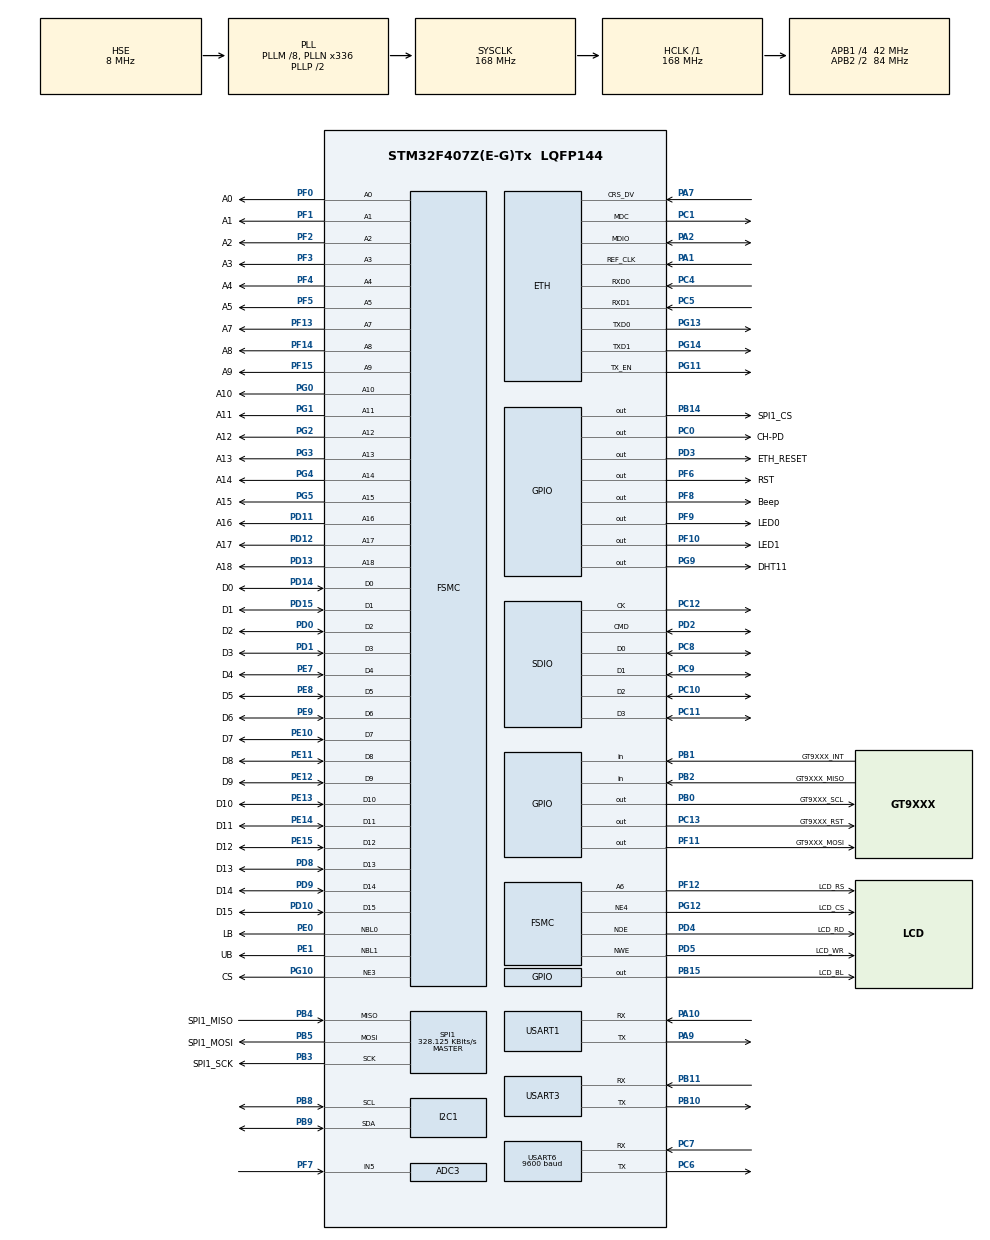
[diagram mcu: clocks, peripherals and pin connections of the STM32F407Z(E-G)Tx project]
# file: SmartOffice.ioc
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ADC3.Channel-0\#ChannelRegularConversion=ADC_CHANNEL_5
ADC3.NbrOfConversionFlag=1
ADC3.Rank-0\#ChannelRegularConversion=1
ADC3.SamplingTime-0\#ChannelRegularConversion=ADC_SAMPLETIME_3CYCLES
Dma.Request0=SDIO_RX
Dma.Request1=SDIO_TX
Dma.Request2=USART3_RX
Dma.Request3=USART3_TX
Dma.SDIO_RX.0.Direction=DMA_PERIPH_TO_MEMORY
Dma.SDIO_RX.0.FIFOMode=DMA_FIFOMODE_ENABLE
Dma.SDIO_RX.0.FIFOThreshold=DMA_FIFO_THRESHOLD_FULL
Dma.SDIO_RX.0.Instance=DMA2_Stream3
Dma.SDIO_RX.0.MemBurst=DMA_MBURST_SINGLE
Dma.SDIO_RX.0.MemDataAlignment=DMA_MDATAALIGN_BYTE
Dma.SDIO_RX.0.MemInc=DMA_MINC_ENABLE
Dma.SDIO_RX.0.Mode=DMA_PFCTRL
Dma.SDIO_RX.0.PeriphBurst=DMA_PBURST_INC4
Dma.SDIO_RX.0.PeriphDataAlignment=DMA_PDATAALIGN_WORD
Dma.SDIO_RX.0.PeriphInc=DMA_PINC_DISABLE
Dma.SDIO_RX.0.Priority=DMA_PRIORITY_LOW
Dma.SDIO_TX.1.Direction=DMA_MEMORY_TO_PERIPH
Dma.SDIO_TX.1.FIFOMode=DMA_FIFOMODE_ENABLE
Dma.SDIO_TX.1.FIFOThreshold=DMA_FIFO_THRESHOLD_FULL
Dma.SDIO_TX.1.Instance=DMA2_Stream6
Dma.SDIO_TX.1.MemBurst=DMA_MBURST_SINGLE
Dma.SDIO_TX.1.MemDataAlignment=DMA_MDATAALIGN_BYTE
Dma.SDIO_TX.1.MemInc=DMA_MINC_ENABLE
Dma.SDIO_TX.1.Mode=DMA_PFCTRL
Dma.SDIO_TX.1.PeriphBurst=DMA_PBURST_INC4
Dma.SDIO_TX.1.PeriphDataAlignment=DMA_PDATAALIGN_WORD
Dma.SDIO_TX.1.PeriphInc=DMA_PINC_DISABLE
Dma.SDIO_TX.1.Priority=DMA_PRIORITY_LOW
Dma.USART3_RX.2.Direction=DMA_PERIPH_TO_MEMORY
Dma.USART3_RX.2.FIFOMode=DMA_FIFOMODE_DISABLE
Dma.USART3_RX.2.Instance=DMA1_Stream1
Dma.USART3_RX.2.MemDataAlignment=DMA_MDATAALIGN_BYTE
Dma.USART3_RX.2.MemInc=DMA_MINC_ENABLE
Dma.USART3_RX.2.Mode=DMA_CIRCULAR
Dma.USART3_RX.2.PeriphDataAlignment=DMA_PDATAALIGN_BYTE
Dma.USART3_RX.2.PeriphInc=DMA_PINC_DISABLE
Dma.USART3_RX.2.Priority=DMA_PRIORITY_LOW
Dma.USART3_TX.3.Direction=DMA_MEMORY_TO_PERIPH
Dma.USART3_TX.3.FIFOMode=DMA_FIFOMODE_DISABLE
Dma.USART3_TX.3.Instance=DMA1_Stream3
Dma.USART3_TX.3.MemDataAlignment=DMA_MDATAALIGN_BYTE
Dma.USART3_TX.3.MemInc=DMA_MINC_ENABLE
Dma.USART3_TX.3.Mode=DMA_NORMAL
Dma.USART3_TX.3.PeriphDataAlignment=DMA_PDATAALIGN_BYTE
Dma.USART3_TX.3.PeriphInc=DMA_PINC_DISABLE
Dma.USART3_TX.3.Priority=DMA_PRIORITY_LOW
ETH.MediaInterface=ETH_MEDIA_INTERFACE_RMII
ETH.PHY_DUPLEX_STATUS=0x2000
ETH.PHY_Name_RMII=userPHY
ETH.PHY_SPEED_STATUS=0x4010
ETH.PHY_SR=0x11
ETH.PhyAddress=0
FATFS._CODE_PAGE=936
FATFS._FS_EXFAT=1
FATFS._USE_LABEL=1
FATFS._USE_LFN=3
FREERTOS.HEAP_NUMBER=5
FREERTOS.MEMORY_ALLOCATION=0
FREERTOS.Tasks01=WebServer,2,256,WebServer_Task,Default,NULL,Dynamic,NULL,NULL;Touch,1,128,Touch_Task,Default,NULL,Dynamic,NULL,NULL;IOT,0,128,IOT_Task,Default,NULL,Dynamic,NULL,NULL;GUI,-1,512,GUI_Task,Default,NULL,Dynamic,NULL,NULL
FREERTOS.configTOTAL_HEAP_SIZE=15360
FSMC.AddressSetupTime1=2
FSMC.BusTurnAroundDuration1=0
FSMC.DataSetupTime1=8
FSMC.DataSetupTime2=60
FSMC.ExtendedAddressSetupTime2=9
FSMC.ExtendedDataSetupTime2=9
FSMC.ExtendedMode2=FSMC_EXTENDED_MODE_ENABLE
FSMC.WriteOperation1=FSMC_WRITE_OPERATION_ENABLE
LWIP.GATEWAY_ADDRESS=010.010.001.001
LWIP.IP_ADDRESS=010.010.001.022
LWIP.LWIP_DHCP=1
LWIP.LWIP_HTTPD=0
LWIP.LWIP_NETIF_LINK_CALLBACK=1
LWIP.MEMP_MEM_MALLOC=1
LWIP.MEM_SIZE=16384
LWIP.NETMASK_ADDRESS=255.255.255.000
LWIP.Version=v2.0.3_Cube
Mcu.Family=STM32F4
Mcu.Name=STM32F407Z(E-G)Tx
Mcu.Package=LQFP144
NVIC.DMA1_Stream1_IRQn=true\:7\:0\:true\:false\:true\:true\:false\:true
NVIC.DMA1_Stream3_IRQn=true\:7\:0\:true\:false\:true\:true\:false\:true
NVIC.DMA2_Stream3_IRQn=true\:6\:0\:true\:false\:true\:true\:false\:true
NVIC.DMA2_Stream6_IRQn=true\:6\:0\:true\:false\:true\:true\:false\:true
NVIC.ETH_IRQn=true\:5\:0\:false\:false\:true\:true\:true\:true
NVIC.PriorityGroup=NVIC_PRIORITYGROUP_4
NVIC.SDIO_IRQn=true\:5\:0\:false\:false\:true\:true\:true\:true
NVIC.TIM1_UP_TIM10_IRQn=true\:0\:0\:false\:false\:true\:false\:false\:true
NVIC.TimeBase=TIM1_UP_TIM10_IRQn
NVIC.TimeBaseIP=TIM1
NVIC.USART3_IRQn=true\:6\:0\:true\:false\:true\:true\:true\:true
PA1.Mode=RMII
PA1.Signal=ETH_REF_CLK
PA10.Mode=Asynchronous
PA10.Signal=USART1_RX
PA13.Mode=Serial_Wire
PA13.Signal=SYS_JTMS-SWDIO
PA14.Mode=Serial_Wire
PA14.Signal=SYS_JTCK-SWCLK
PA2.Mode=RMII
PA2.Signal=ETH_MDIO
PA7.Mode=RMII
PA7.Signal=ETH_CRS_DV
PA9.Mode=Asynchronous
PA9.Signal=USART1_TX
PB0.GPIO_Label=GT9XXX_SCL
PB0.GPIO_PuPd=GPIO_PULLUP
PB0.GPIO_Speed=GPIO_SPEED_FREQ_VERY_HIGH
PB0.Signal=GPIO_Output
PB1.GPIO_Label=GT9XXX_INT
PB1.Signal=GPIO_Input
PB10.Mode=Asynchronous
PB10.Signal=USART3_TX
PB11.Mode=Asynchronous
PB11.Signal=USART3_RX
PB14.GPIO_Label=SPI1_CS
PB14.GPIO_PuPd=GPIO_PULLUP
PB14.GPIO_Speed=GPIO_SPEED_FREQ_HIGH
PB14.PinState=GPIO_PIN_SET
PB14.Signal=GPIO_Output
PB15.GPIO_Label=LCD_BL
PB15.GPIO_PuPd=GPIO_PULLDOWN
PB15.GPIO_Speed=GPIO_SPEED_FREQ_HIGH
PB15.PinState=GPIO_PIN_SET
PB15.Signal=GPIO_Output
PB2.GPIO_Label=GT9XXX_MISO
PB2.GPIO_PuPd=GPIO_PULLUP
PB2.Signal=GPIO_Input
PB3.GPIO_Label=SPI1_SCK
PB3.GPIO_PuPd=GPIO_PULLUP
PB3.Mode=Full_Duplex_Master
PB3.Signal=SPI1_SCK
PB4.GPIO_Label=SPI1_MISO
PB4.GPIO_PuPd=GPIO_PULLUP
PB4.Mode=Full_Duplex_Master
PB4.Signal=SPI1_MISO
PB5.GPIO_Label=SPI1_MOSI
PB5.GPIO_PuPd=GPIO_PULLUP
PB5.Mode=Full_Duplex_Master
PB5.Signal=SPI1_MOSI
PB8.Mode=I2C
PB8.Signal=I2C1_SCL
PB9.Mode=I2C
PB9.Signal=I2C1_SDA
PC0.GPIO_Label=CH-PD
PC0.GPIO_PuPd=GPIO_NOPULL
PC0.GPIO_Speed=GPIO_SPEED_FREQ_LOW
PC0.PinState=GPIO_PIN_SET
PC0.Signal=GPIO_Output
PC1.Mode=RMII
PC1.Signal=ETH_MDC
PC10.GPIO_PuPd=GPIO_PULLUP
PC10.Mode=SD_4_bits_Wide_bus
PC10.Signal=SDIO_D2
PC11.GPIO_PuPd=GPIO_PULLUP
PC11.Mode=SD_4_bits_Wide_bus
PC11.Signal=SDIO_D3
PC12.GPIO_PuPd=GPIO_PULLUP
PC12.Mode=SD_4_bits_Wide_bus
PC12.Signal=SDIO_CK
PC13-ANTI_TAMP.GPIO_Label=GT9XXX_RST
PC13-ANTI_TAMP.GPIO_PuPd=GPIO_PULLUP
PC13-ANTI_TAMP.Signal=GPIO_Output
PC4.Mode=RMII
PC4.Signal=ETH_RXD0
PC5.Mode=RMII
PC5.Signal=ETH_RXD1
PC6.Mode=Asynchronous
PC6.Signal=USART6_TX
PC7.Mode=Asynchronous
PC7.Signal=USART6_RX
PC8.GPIO_PuPd=GPIO_PULLUP
PC8.Mode=SD_4_bits_Wide_bus
PC8.Signal=SDIO_D0
PC9.GPIO_PuPd=GPIO_PULLUP
PC9.Mode=SD_4_bits_Wide_bus
PC9.Signal=SDIO_D1
PD0.GPIO_Label=D2
PD0.GPIO_PuPd=GPIO_PULLUP
PD0.Signal=FSMC_D2_DA2
PD1.GPIO_Label=D3
PD1.GPIO_PuPd=GPIO_PULLUP
PD1.Signal=FSMC_D3_DA3
PD10.GPIO_Label=D15
PD10.GPIO_PuPd=GPIO_PULLUP
PD10.Signal=FSMC_D15_DA15
PD11.GPIO_Label=A16
PD11.GPIO_PuPd=GPIO_PULLUP
PD11.Signal=FSMC_A16_CLE
PD12.GPIO_Label=A17
PD12.GPIO_PuPd=GPIO_PULLUP
PD12.Signal=FSMC_A17_ALE
PD13.GPIO_Label=A18
PD13.GPIO_PuPd=GPIO_PULLUP
PD13.Signal=FSMC_A18
PD14.GPIO_Label=D0
PD14.GPIO_PuPd=GPIO_PULLUP
PD14.Signal=FSMC_D0_DA0
PD15.GPIO_Label=D1
PD15.GPIO_PuPd=GPIO_PULLUP
PD15.Signal=FSMC_D1_DA1
PD2.GPIO_PuPd=GPIO_PULLUP
PD2.Mode=SD_4_bits_Wide_bus
PD2.Signal=SDIO_CMD
PD3.GPIO_Label=ETH_RESET
PD3.GPIO_Speed=GPIO_SPEED_FREQ_VERY_HIGH
PD3.PinState=GPIO_PIN_SET
PD3.Signal=GPIO_Output
PD4.GPIO_Label=LCD_RD
PD4.GPIO_PuPd=GPIO_PULLUP
PD4.Signal=FSMC_NOE
PD5.GPIO_Label=LCD_WR
PD5.GPIO_PuPd=GPIO_PULLUP
PD5.Signal=FSMC_NWE
PD8.GPIO_Label=D13
PD8.GPIO_PuPd=GPIO_PULLUP
PD8.Signal=FSMC_D13_DA13
PD9.GPIO_Label=D14
PD9.GPIO_PuPd=GPIO_PULLUP
PD9.Signal=FSMC_D14_DA14
PE0.GPIO_Label=LB
PE0.GPIO_PuPd=GPIO_PULLUP
PE0.Signal=FSMC_NBL0
PE1.GPIO_Label=UB
PE1.GPIO_PuPd=GPIO_PULLUP
PE1.Signal=FSMC_NBL1
PE10.GPIO_Label=D7
PE10.GPIO_PuPd=GPIO_PULLUP
PE10.Signal=FSMC_D7_DA7
PE11.GPIO_Label=D8
PE11.GPIO_PuPd=GPIO_PULLUP
PE11.Signal=FSMC_D8_DA8
PE12.GPIO_Label=D9
PE12.GPIO_PuPd=GPIO_PULLUP
PE12.Signal=FSMC_D9_DA9
PE13.GPIO_Label=D10
PE13.GPIO_PuPd=GPIO_PULLUP
PE13.Signal=FSMC_D10_DA10
PE14.GPIO_Label=D11
PE14.GPIO_PuPd=GPIO_PULLUP
PE14.Signal=FSMC_D11_DA11
PE15.GPIO_Label=D12
PE15.GPIO_PuPd=GPIO_PULLUP
PE15.Signal=FSMC_D12_DA12
PE7.GPIO_Label=D4
PE7.GPIO_PuPd=GPIO_PULLUP
PE7.Signal=FSMC_D4_DA4
PE8.GPIO_Label=D5
PE8.GPIO_PuPd=GPIO_PULLUP
PE8.Signal=FSMC_D5_DA5
PE9.GPIO_Label=D6
PE9.GPIO_PuPd=GPIO_PULLUP
PE9.Signal=FSMC_D6_DA6
PF0.GPIO_Label=A0
PF0.GPIO_PuPd=GPIO_PULLUP
PF0.Signal=FSMC_A0
PF1.GPIO_Label=A1
PF1.GPIO_PuPd=GPIO_PULLUP
PF1.Signal=FSMC_A1
PF10.GPIO_Label=LED1
PF10.GPIO_ModeDefaultOutputPP=GPIO_MODE_OUTPUT_PP
PF10.GPIO_PuPd=GPIO_PULLUP
PF10.GPIO_Speed=GPIO_SPEED_FREQ_HIGH
PF10.PinState=GPIO_PIN_SET
PF10.Signal=GPIO_Output
PF11.GPIO_Label=GT9XXX_MOSI
PF11.GPIO_ModeDefaultOutputPP=GPIO_MODE_OUTPUT_OD
PF11.GPIO_PuPd=GPIO_PULLUP
PF11.GPIO_Speed=GPIO_SPEED_FREQ_VERY_HIGH
PF11.Signal=GPIO_Output
PF12.GPIO_Label=LCD_RS
PF12.GPIO_PuPd=GPIO_PULLUP
PF12.Signal=FSMC_A6
PF13.GPIO_Label=A7
PF13.GPIO_PuPd=GPIO_PULLUP
PF13.Signal=FSMC_A7
PF14.GPIO_Label=A8
PF14.GPIO_PuPd=GPIO_PULLUP
PF14.Signal=FSMC_A8
PF15.GPIO_Label=A9
PF15.GPIO_PuPd=GPIO_PULLUP
PF15.Signal=FSMC_A9
PF2.GPIO_Label=A2
PF2.GPIO_PuPd=GPIO_PULLUP
PF2.Signal=FSMC_A2
PF3.GPIO_Label=A3
PF3.GPIO_PuPd=GPIO_PULLUP
PF3.Signal=FSMC_A3
PF4.GPIO_Label=A4
PF4.GPIO_PuPd=GPIO_PULLUP
PF4.Signal=FSMC_A4
PF5.GPIO_Label=A5
PF5.GPIO_PuPd=GPIO_PULLUP
PF5.Signal=FSMC_A5
PF6.GPIO_Label=RST
PF6.PinState=GPIO_PIN_SET
PF6.Signal=GPIO_Output
PF7.Mode=IN5
PF7.Signal=ADC3_IN5
PF8.GPIO_Label=Beep
PF8.GPIO_ModeDefaultOutputPP=GPIO_MODE_OUTPUT_PP
PF8.GPIO_PuPd=GPIO_PULLDOWN
PF8.GPIO_Speed=GPIO_SPEED_FREQ_VERY_HIGH
PF8.Signal=GPIO_Output
PF9.GPIO_Label=LED0
PF9.GPIO_PuPd=GPIO_PULLUP
PF9.GPIO_Speed=GPIO_SPEED_FREQ_HIGH
PF9.PinState=GPIO_PIN_SET
PF9.Signal=GPIO_Output
PG0.GPIO_Label=A10
PG0.GPIO_PuPd=GPIO_PULLUP
PG0.Signal=FSMC_A10
PG1.GPIO_Label=A11
PG1.GPIO_PuPd=GPIO_PULLUP
PG1.Signal=FSMC_A11
PG10.GPIO_Label=CS
PG10.GPIO_PuPd=GPIO_PULLUP
PG10.Mode=NorPsramChipSelect3_1
PG10.Signal=FSMC_NE3
PG11.Mode=RMII
PG11.Signal=ETH_TX_EN
PG12.GPIO_Label=LCD_CS
PG12.GPIO_PuPd=GPIO_PULLUP
PG12.Mode=NorPsramChipSelect4_2
PG12.Signal=FSMC_NE4
PG13.Mode=RMII
PG13.Signal=ETH_TXD0
PG14.Mode=RMII
PG14.Signal=ETH_TXD1
PG2.GPIO_Label=A12
PG2.GPIO_PuPd=GPIO_PULLUP
PG2.Signal=FSMC_A12
PG3.GPIO_Label=A13
PG3.GPIO_PuPd=GPIO_PULLUP
PG3.Signal=FSMC_A13
PG4.GPIO_Label=A14
PG4.GPIO_PuPd=GPIO_PULLUP
PG4.Signal=FSMC_A14
PG5.GPIO_Label=A15
PG5.GPIO_PuPd=GPIO_PULLUP
PG5.Signal=FSMC_A15
PG9.GPIO_Label=DHT11
PG9.GPIO_ModeDefaultOutputPP=GPIO_MODE_OUTPUT_OD
PG9.GPIO_PuPd=GPIO_PULLUP
PG9.GPIO_Speed=GPIO_SPEED_FREQ_VERY_HIGH
PG9.PinState=GPIO_PIN_SET
PG9.Signal=GPIO_Output
PH0-OSC_IN.Mode=HSE-External-Oscillator
PH0-OSC_IN.Signal=RCC_OSC_IN
PH1-OSC_OUT.Mode=HSE-External-Oscillator
PH1-OSC_OUT.Signal=RCC_OSC_OUT
ProjectManager.HeapSize=0x400
ProjectManager.StackSize=0x2000
ProjectManager.TargetToolchain=MDK-ARM V5
RCC.48MHZClocksFreq_Value=48000000
RCC.AHBFreq_Value=168000000
RCC.APB1CLKDivider=RCC_HCLK_DIV4
RCC.APB1Freq_Value=42000000
RCC.APB1TimFreq_Value=84000000
RCC.APB2CLKDivider=RCC_HCLK_DIV2
RCC.APB2Freq_Value=84000000
RCC.APB2TimFreq_Value=168000000
RCC.CortexFreq_Value=168000000
RCC.HCLKFreq_Value=168000000
RCC.HSE_VALUE=8000000
RCC.HSI_VALUE=16000000
RCC.LSE_VALUE=32768
RCC.PLLM=8
RCC.PLLN=336
RCC.PLLQ=7
RCC.PLLSourceVirtual=RCC_PLLSOURCE_HSE
RCC.SYSCLKFreq_VALUE=168000000
RCC.SYSCLKSource=RCC_SYSCLKSOURCE_PLLCLK
RCC.VCOOutputFreq_Value=336000000
SDIO.HardwareFlowControl=SDIO_HARDWARE_FLOW_CONTROL_ENABLE
SH.FSMC_A0.0=FSMC_A0,19b-a1
SH.FSMC_A1.0=FSMC_A1,19b-a1
SH.FSMC_A10.0=FSMC_A10,19b-a1
SH.FSMC_A11.0=FSMC_A11,19b-a1
SH.FSMC_A12.0=FSMC_A12,19b-a1
SH.FSMC_A13.0=FSMC_A13,19b-a1
SH.FSMC_A14.0=FSMC_A14,19b-a1
SH.FSMC_A15.0=FSMC_A15,19b-a1
SH.FSMC_A16_CLE.0=FSMC_A16,19b-a1
SH.FSMC_A17_ALE.0=FSMC_A17,19b-a1
SH.FSMC_A18.0=FSMC_A18,19b-a1
SH.FSMC_A2.0=FSMC_A2,19b-a1
SH.FSMC_A3.0=FSMC_A3,19b-a1
SH.FSMC_A4.0=FSMC_A4,19b-a1
SH.FSMC_A5.0=FSMC_A5,19b-a1
SH.FSMC_A6.0=FSMC_A6,A6_2
SH.FSMC_A6.1=FSMC_A6,19b-a1
SH.FSMC_A7.0=FSMC_A7,19b-a1
SH.FSMC_A8.0=FSMC_A8,19b-a1
SH.FSMC_A9.0=FSMC_A9,19b-a1
SH.FSMC_D0_DA0.0=FSMC_D0,16b-d2
SH.FSMC_D0_DA0.1=FSMC_D0,16b-d1
SH.FSMC_D10_DA10.0=FSMC_D10,16b-d2
SH.FSMC_D10_DA10.1=FSMC_D10,16b-d1
SH.FSMC_D11_DA11.0=FSMC_D11,16b-d2
SH.FSMC_D11_DA11.1=FSMC_D11,16b-d1
SH.FSMC_D12_DA12.0=FSMC_D12,16b-d2
SH.FSMC_D12_DA12.1=FSMC_D12,16b-d1
SH.FSMC_D13_DA13.0=FSMC_D13,16b-d2
SH.FSMC_D13_DA13.1=FSMC_D13,16b-d1
SH.FSMC_D14_DA14.0=FSMC_D14,16b-d2
SH.FSMC_D14_DA14.1=FSMC_D14,16b-d1
SH.FSMC_D15_DA15.0=FSMC_D15,16b-d2
SH.FSMC_D15_DA15.1=FSMC_D15,16b-d1
SH.FSMC_D1_DA1.0=FSMC_D1,16b-d2
SH.FSMC_D1_DA1.1=FSMC_D1,16b-d1
SH.FSMC_D2_DA2.0=FSMC_D2,16b-d2
SH.FSMC_D2_DA2.1=FSMC_D2,16b-d1
SH.FSMC_D3_DA3.0=FSMC_D3,16b-d2
SH.FSMC_D3_DA3.1=FSMC_D3,16b-d1
SH.FSMC_D4_DA4.0=FSMC_D4,16b-d2
SH.FSMC_D4_DA4.1=FSMC_D4,16b-d1
SH.FSMC_D5_DA5.0=FSMC_D5,16b-d2
SH.FSMC_D5_DA5.1=FSMC_D5,16b-d1
SH.FSMC_D6_DA6.0=FSMC_D6,16b-d2
SH.FSMC_D6_DA6.1=FSMC_D6,16b-d1
SH.FSMC_D7_DA7.0=FSMC_D7,16b-d2
SH.FSMC_D7_DA7.1=FSMC_D7,16b-d1
SH.FSMC_D8_DA8.0=FSMC_D8,16b-d2
SH.FSMC_D8_DA8.1=FSMC_D8,16b-d1
SH.FSMC_D9_DA9.0=FSMC_D9,16b-d2
SH.FSMC_D9_DA9.1=FSMC_D9,16b-d1
SH.FSMC_NBL0.0=FSMC_NBL0,2ByteEnable1
SH.FSMC_NBL1.0=FSMC_NBL1,2ByteEnable1
SH.FSMC_NOE.0=FSMC_NOE,Lcd2
SH.FSMC_NOE.1=FSMC_NOE,Sram1
SH.FSMC_NWE.0=FSMC_NWE,Lcd2
SH.FSMC_NWE.1=FSMC_NWE,Sram1
SPI1.BaudRatePrescaler=SPI_BAUDRATEPRESCALER_256
SPI1.CLKPhase=SPI_PHASE_2EDGE
SPI1.CLKPolarity=SPI_POLARITY_HIGH
SPI1.CalculateBaudRate=328.125 KBits/s
SPI1.Direction=SPI_DIRECTION_2LINES
SPI1.Mode=SPI_MODE_MASTER
SPI1.VirtualType=VM_MASTER
USART1.VirtualMode=VM_ASYNC
USART3.VirtualMode=VM_ASYNC
USART6.BaudRate=9600
USART6.VirtualMode=VM_ASYNC
VP_CRC_VS_CRC.Mode=CRC_Activate
VP_FATFS_VS_Generic.Mode=User_defined
VP_FATFS_VS_SDIO.Mode=SDIO
VP_FREERTOS_VS_CMSIS_V1.Mode=CMSIS_V1
VP_LWIP_VS_Enabled.Mode=Enabled
VP_SYS_VS_tim1.Mode=TIM1
board=custom

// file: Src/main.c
/* USER CODE BEGIN Header */
/**
  ******************************************************************************
  * @file           : main.c
  * @brief          : Main program body
  ******************************************************************************
  * @attention
  *
  * <h2><center>&copy; Copyright (c) 2024 STMicroelectronics.
  * All rights reserved.</center></h2>
  *
  * This software component is licensed by ST under BSD 3-Clause license,
  * the "License"; You may not use this file except in compliance with the
  * License. You may obtain a copy of the License at:
  *                        opensource.org/licenses/BSD-3-Clause
  *
  ******************************************************************************
  */
/* USER CODE END Header */

#include "main.h"
#include "cmsis_os.h"
#include "adc.h"
#include "crc.h"
#include "dma.h"
#include "fatfs.h"
#include "i2c.h"
#include "lwip.h"
#include "sdio.h"
#include "spi.h"
#include "usart.h"
#include "gpio.h"
#include "fsmc.h"

/* USER CODE BEGIN Includes */
#include "sram.h"  //sram_init
#include "mymalloc.h"  //my_mem_init

#include "FreeRTOS.h"
#include "task.h"

#include "delay.h"
#include "lcd.h"

#include "lwipopts.h"  //lwipopts.h

#include "GUI.h"  //GUI_PID_STATE
#include <string.h>
#include "fonts.h"
#include "icon.h"

#include "web.h"  //_webs_info
/* USER CODE END Includes */

/* USER CODE BEGIN PV */
// 定义堆区域数�?
// Freertos heap5
HeapRegion_t xHeapRegions[] = {
    { ( uint8_t * ) FreeRTOS_Heap5_ExRAM_ADDR, FreeRTOS_Heap5_ExRAM_SIZE },  // 定义�?0x68000000�?始的40K字节内存�?
    { NULL, 0 }                            // 终止数组
};

void configureHeapRegions(void)
{
    vPortDefineHeapRegions(xHeapRegions);  // 定义堆区�?
}

//uint8_t paddr[20] = {0};                  /* 存放内存EXSRAM使用�? */
uint8_t* paddr;
uint16_t memused = 0;                     /* 内存使用百分�? */

//uint8_t lcd_id[12];
uint8_t* lcd_id;

//uint16_t colors[12] = {WHITE, BLACK, BLUE, RED, MAGENTA, GREEN, CYAN, YELLOW, BRRED, GRAY, LGRAY, BROWN};uint8_t color_index = 0;
uint8_t cur_brightness;
//uint8_t* str[23];
FATFS* SDFatFS; /* File system object for SD logical drive */
FATFS* USERFatFS; /* File system object for USER logical drive */

_font_info* ftinfo;
_icon_info* iconftinfo;
_webs_info* webstinfo;

uint8_t* uart3_rx_buffer;
uint8_t* uart3_rx_data;

//char FAN_ip_address[MAX_IP_LENGTH] = {0};  //风扇模块ip地址
//char MasterLight_ip_address[MAX_IP_LENGTH] = {0};  //主灯模块ip地址
//char SpotLight_ip_address[MAX_IP_LENGTH] = {0};  //射灯模块ip地址
char ETH_ip_address[MAX_IP_LENGTH] = {0};  //有线网络ip地址
/* USER CODE END PV */

void SystemClock_Config(void);
void MX_FREERTOS_Init(void);

int main(void)
{

  /* MCU Configuration--------------------------------------------------------*/

  /* Reset of all peripherals, Initializes the Flash interface and the Systick. */
  HAL_Init();

  /* Configure the system clock */
  SystemClock_Config();

  /* Initialize all configured peripherals */
  MX_GPIO_Init();
  MX_DMA_Init();
  MX_USART1_UART_Init();
  MX_FSMC_Init();
  MX_I2C1_Init();
  MX_CRC_Init();
  MX_SPI1_Init();
  MX_ADC3_Init();
  MX_SDIO_SD_Init();
  MX_USART3_UART_Init();
  MX_USART6_UART_Init();
  /* USER CODE BEGIN 2 */
	// 调用配置堆区域的函数
	//configureHeapRegions();  //FreeRTOS定义heap5的堆区地�?范围
	//移动到SRAM和自定义内存池初始化完成之后
	printf("main.c---------------------------->\n");

	sram_init();                        /* 外扩SRAM初始�? */

	//my_mem_init(SRAMIN);                /* 初始化内部SRAM内存�? */
	my_mem_init(SRAMEX);                /* 初始化外部SRAM内存�? */
	my_mem_init(SRAMCCM);               /* 初始化内部CCM内存�? */

	printf("Init EXSRAM\n");
	printf("Init SRAM CCM\n");

	configureHeapRegions();  //FreeRTOS定义heap5的堆区地�?范围

	printf("Asigned FreeRTOS heap5 Range\n");

	//paddr = (uint8_t *)mymalloc(0, 20);
	paddr = (uint8_t *)mymalloc(1, 20);
	memset(paddr, 0, 20);

	//因为将外扩SRAM的开�?40KB给FreeRTOS使用，所以要将这部分在内存管理表中对应的表项赋�?�为非零，表示已经被占用了，防止影响FreeRTOS的堆空间
	my_mem_occupy(SRAMEX, FreeRTOS_Heap5_ExRAM_SIZE);  //40*1024

	memused = my_mem_perused(SRAMEX);
	sprintf((char *)paddr, "%d.%01d%%", memused / 10, memused % 10);
	printf("SRAMEX   USED: %s\n", (char *)paddr);

	printf("Allocate some space for LWIP in EXSRAM\n");

	//因为在外扩SRAM紧跟40KBFreeRTOS的空间后面给LWIP分配MEM_SIZE大小的空间，�?以要将这部分在内存管理表中对应的表项赋�?�为非零
	my_mem_occupy_from(SRAMEX, FreeRTOS_Heap5_ExRAM_SIZE, MEM_SIZE);  //40*1024�? 1600
	memused = my_mem_perused(SRAMEX);
	sprintf((char *)paddr, "%d.%01d%%", memused / 10, memused % 10);
	printf("SRAMEX   USED: %s\n", (char *)paddr);
	/*
	lcd_id = (uint8_t *)mymalloc(2, 12);
	memset(lcd_id, 0, 12);

	SDFatFS = (FATFS *)mymalloc(2, sizeof(FATFS));
	memset(SDFatFS, 0, sizeof(FATFS));

	USERFatFS = (FATFS *)mymalloc(2, sizeof(FATFS));
	memset(USERFatFS, 0, sizeof(FATFS));

	ftinfo = (_font_info *)mymalloc(2, sizeof(_font_info));
	memset(ftinfo, 0, sizeof(_font_info));

	iconftinfo = (_icon_info *)mymalloc(2, sizeof(_icon_info));
	memset(iconftinfo, 0, sizeof(_icon_info));

	webstinfo = (_webs_info *)mymalloc(2, sizeof(_webs_info));
	memset(webstinfo, 0, sizeof(_webs_info));
	*/
	//上面结构体及变量从外扩SRAM移动到CCM�?

	uart3_rx_buffer = (uint8_t *)mymalloc(2, BUFFER_WINDOW*sizeof(uint8_t));  //不能移动到CCM中，否则串口中断会卡�?
	memset(uart3_rx_buffer, 0, BUFFER_WINDOW*sizeof(uint8_t));

	uart3_rx_data = (uint8_t *)mymalloc(2, BUFFER_WINDOW*sizeof(uint8_t));  //不能移动到CCM中，否则串口中断会卡歿
	memset(uart3_rx_data, 0, BUFFER_WINDOW*sizeof(uint8_t));

	printf("Allocated some struct and variables in EXSRAM\n");

	memused = my_mem_perused(SRAMEX);
	sprintf((char *)paddr, "%d.%01d%%", memused / 10, memused % 10);
	printf("SRAMEX   USED: %s\n", (char *)paddr);

	//在CCM中分�?
	lcd_id = (uint8_t *)mymalloc(1, 12);
	memset(lcd_id, 0, 12);

	SDFatFS = (FATFS *)mymalloc(1, sizeof(FATFS));
	memset(SDFatFS, 0, sizeof(FATFS));

	USERFatFS = (FATFS *)mymalloc(1, sizeof(FATFS));
	memset(USERFatFS, 0, sizeof(FATFS));

	ftinfo = (_font_info *)mymalloc(1, sizeof(_font_info));
	memset(ftinfo, 0, sizeof(_font_info));

	iconftinfo = (_icon_info *)mymalloc(1, sizeof(_icon_info));
	memset(iconftinfo, 0, sizeof(_icon_info));

	webstinfo = (_webs_info *)mymalloc(1, sizeof(_webs_info));
	memset(webstinfo, 0, sizeof(_webs_info));

	printf("Allocated some struct and variables in SRAM CCM\n");

	memused = my_mem_perused(SRAMCCM);
	sprintf((char *)paddr, "%d.%01d%%", memused / 10, memused % 10);
	printf("SRAMCCM   USED: %s\n", (char *)paddr);

	printf("----------------------------------|\n\n");
  /* USER CODE END 2 */

  /* Call init function for freertos objects (in freertos.c) */
  MX_FREERTOS_Init();

  /* Start scheduler */
  osKernelStart();

  /* We should never get here as control is now taken by the scheduler */

  /* Infinite loop */
  while (1)
  {

  }
}

void SystemClock_Config(void)
{
  RCC_OscInitTypeDef RCC_OscInitStruct = {0};
  RCC_ClkInitTypeDef RCC_ClkInitStruct = {0};

  /** Configure the main internal regulator output voltage
  */
  __HAL_RCC_PWR_CLK_ENABLE();
  __HAL_PWR_VOLTAGESCALING_CONFIG(PWR_REGULATOR_VOLTAGE_SCALE1);
  /** Initializes the CPU, AHB and APB busses clocks
  */
  RCC_OscInitStruct.OscillatorType = RCC_OSCILLATORTYPE_HSE;
  RCC_OscInitStruct.HSEState = RCC_HSE_ON;
  RCC_OscInitStruct.PLL.PLLState = RCC_PLL_ON;
  RCC_OscInitStruct.PLL.PLLSource = RCC_PLLSOURCE_HSE;
  RCC_OscInitStruct.PLL.PLLM = 8;
  RCC_OscInitStruct.PLL.PLLN = 336;
  RCC_OscInitStruct.PLL.PLLP = RCC_PLLP_DIV2;
  RCC_OscInitStruct.PLL.PLLQ = 7;
  if (HAL_RCC_OscConfig(&RCC_OscInitStruct) != HAL_OK)
  {
    Error_Handler();
  }
  /** Initializes the CPU, AHB and APB busses clocks
  */
  RCC_ClkInitStruct.ClockType = RCC_CLOCKTYPE_HCLK|RCC_CLOCKTYPE_SYSCLK
                              |RCC_CLOCKTYPE_PCLK1|RCC_CLOCKTYPE_PCLK2;
  RCC_ClkInitStruct.SYSCLKSource = RCC_SYSCLKSOURCE_PLLCLK;
  RCC_ClkInitStruct.AHBCLKDivider = RCC_SYSCLK_DIV1;
  RCC_ClkInitStruct.APB1CLKDivider = RCC_HCLK_DIV4;
  RCC_ClkInitStruct.APB2CLKDivider = RCC_HCLK_DIV2;

  if (HAL_RCC_ClockConfig(&RCC_ClkInitStruct, FLASH_LATENCY_5) != HAL_OK)
  {
    Error_Handler();
  }
}

/* USER CODE BEGIN 4 */
/*
void emwin_test_touch(void){
	GUI_PID_STATE State;
	GUI_Init();
	GUI_SetBkColor(GUI_BLUE);
	GUI_SetFont(&GUI_Font20_ASCII);
	GUI_SetColor(GUI_YELLOW);
	GUI_Clear();
	while(1){
		//执行触摸笔检�?
		GUI_TOUCH_Exec();
		//获取触摸笔状态�??
		GUI_TOUCH_GetState(&State);
		//是否按下
		if(State.Pressed){
			//打印触摸笔坐标信�?
			GUI_DispStringAt("X:", 0, 0);
			GUI_DispDecAt(State.x, 32, 0, 4);
			GUI_DispStringAt("Y:", 0, 24);
			GUI_DispDecAt(State.y, 32, 24, 4);

			GUI_DispStringAt("EXIT", lcddev.width - 40, 0);
		}

		delay_ms(10);
		if (State.x > lcddev.width - 40 && State.y < 20) //按EXIT
		{
				GUI_SetBkColor(GUI_WHITE);
				GUI_Clear();
				return;  //�?出测试死循环
		}
	}
}
*/
/* USER CODE END 4 */

void HAL_TIM_PeriodElapsedCallback(TIM_HandleTypeDef *htim)
{
  if (htim->Instance == TIM1) {
    HAL_IncTick();
  }
}

void Error_Handler(void)
{
}

/************************ (C) COPYRIGHT STMicroelectronics *****END OF FILE****/

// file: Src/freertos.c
/* USER CODE BEGIN Header */
/**
  ******************************************************************************
  * File Name          : freertos.c
  * Description        : Code for freertos applications
  ******************************************************************************
  * @attention
  *
  * <h2><center>&copy; Copyright (c) 2024 STMicroelectronics.
  * All rights reserved.</center></h2>
  *
  * This software component is licensed by ST under Ultimate Liberty license
  * SLA0044, the "License"; You may not use this file except in compliance with
  * the License. You may obtain a copy of the License at:
  *                             www.st.com/SLA0044
  *
  ******************************************************************************
  */
/* USER CODE END Header */

#include "FreeRTOS.h"
#include "task.h"
#include "main.h"
#include "cmsis_os.h"

/* USER CODE BEGIN Includes */
#include "delay.h"
#include "lcd.h"
#include "stdio.h"  //sprintf

#include "touch.h"  //tp_dev
#include "norflash.h"  //norflash_init

#include "dht11.h"  //dht11_init、dht11_read_data

#include "lsens.h"  //lsens_init

#include "GUI.h"  //GUI_TOUCH_Exec

#include "diskio.h"

#include "fatfs.h"  //SDFatFS、USERFatFS
#include "fonts.h"  //fonts_update_font
#include "mymalloc.h"  //mymalloc
#include "icon.h"

#include "icon_read.h"  //read_icons

#include "esp8266.h"
#include <string.h>
//#include "esp8266_web.h"
#include "esp8266_web_DMA.h"

#include "ip4_addr.h"  //ip4_addr_t
#include "lwip/netif.h"  //struct netif
#include "ip4_addr.h"  //ip4_addr_isvalid

//#include "init.h"
//#include "tcp.h"
//#include "dhcp.h"
//#include "api.h"
//#include "httpd.h"

#include "eth_web.h"
#include "web.h"  //webs_init

#include "usart3_dma.h"  //USART3_Init_DMA

#include "wireless_web.h"  //Listen_Thread_Wireless init_uart3_rx_queue
/* USER CODE END Includes */

/* USER CODE BEGIN PM */
// 手动声明 ip4_addr_isvalid 函数
int ip4_addr_isvalid(const ip4_addr_t *addr);
/* USER CODE END PM */

/* USER CODE BEGIN Variables */
//lcd
extern uint8_t lcd_id[12]; //main.c
//extern uint16_t colors[];  //main.c
//extern uint8_t color_index;  //main.c

uint16_t id;  //norflash id

uint8_t t = 0;
uint16_t temperature;  //温度
uint16_t humidity;  //湿度
uint16_t adcx;  //亮度

unsigned long recv = 0;

//TaskHandle_t xMountDisksTaskHandle;
// 创建二�?�信号量句柄
SemaphoreHandle_t xBinarySemaphoreCheckFontsAndIconBin;
//更新字库相关
extern uint8_t fonts_update_res;

// 创建二�?�信号量句柄
SemaphoreHandle_t xBinarySemaphoreFont;

// 创建二值信号量句柄
SemaphoreHandle_t xBinarySemaphoreICON;

//esp8266 uart3
//uint8_t uart3_rx_buffer[RX_BUFFER_SIZE];
uint16_t uart3_rx_index = 0;
uint8_t Uart3FramFinishFlag = 0;

// 创建互斥信号量句�?
SemaphoreHandle_t xMutexEsp8266;

// 创建二值信号量句柄
SemaphoreHandle_t xBinaryWireless;

extern struct netif gnetif;  //lwip.c

extern uint8_t* paddr;
extern uint16_t memused;                     /* 内存使用百分�? */

extern uint8_t AT_Flag;  //stm32f4xx_it.c
/* USER CODE END Variables */
osThreadId WebServerHandle;
osThreadId TouchHandle;
osThreadId IOTHandle;
osThreadId GUIHandle;

/* USER CODE BEGIN FunctionPrototypes */
extern void MainTask(void);

void init_disks(){
	while(disk_initialize(0)){  //SD卡初始化
		//printf("SD Card Error!\n");
		delay_ms(500);
		//printf("Please Check!\n");
		delay_ms(500);
	}
	//printf("SD Card init OK!\n");
	disk_ioctl(0, 1, (void*)&recv);
	//printf("SD sector count: %d\n", (int)recv);
	while(disk_initialize(1)){  //NORFlash初始�?
			//printf("Noflash Error!\n");
			delay_ms(500);
			//printf("Please Check!\n");
			delay_ms(500);
	}
	//printf("Noflash init OK!\n");
	disk_ioctl(1, 1, (void*)&recv);
	//printf("noflash sector count: %d\n", (int)recv);
}

void fmout_sd(uint8_t opt){
	//uint8_t work_buff[512] = {0};  //缓冲�?
	uint8_t * work_buff = (uint8_t *)mymalloc(2, 512);
	uint8_t res = 0;
	res = f_mount(SDFatFS, "0:", opt);        // 挂载SD�?
	printf("f_mount sd res:%u\n", res);
	if(FR_OK == res){
		printf("SD Disk Mount Successed!\n");     //SD卡成功挂�?
	}
	if (res == 0X0D) {               // SD卡挂载失�? 文件系统错误
			//printf("sd fs error!\n");
			//printf("SD Disk Formatting...\n");
			res = f_mkfs("0:", 0, 0, work_buff, _MAX_SS);                                            /* 格式化SD,0:,盘符;0,使用默认格式化参�? */

			if (res == 0){
					f_setlabel((const TCHAR *)"0:ALIENTEK_SD");                                    /* 设置SD磁盘的名字为：ALIENTEK_SD */
					//printf("SD Disk Format Finish\n");     // 格式化成�?
			}	else	{
					//printf("SD Disk Format Error\n");     // 格式化失�?
			}
	}
	myfree(2, work_buff);
}

void fmout_norflash(uint8_t opt){
	uint8_t * work_buff = (uint8_t *)mymalloc(2, 512);
	uint8_t res = 0;
	res = f_mount(USERFatFS, "1:", opt);  // 挂载NORFlash
	printf("f_mount flash res:%u\n", res);
	if(FR_OK == res){
		printf("Flash Disk Mount Successed!\n");     // 挂载NORFlash成功
	}
	if (res == 0X0D) {                // NORFlash文件系统损坏
			//printf("flash fs error!\n");
			//printf("Flash Disk Formatting...\n");
			res = f_mkfs("1:", 0, 0, work_buff, _MAX_SS);                                            /* 格式化FLASH,1:,盘符;1,使用默认格式化参�? */

			if (res == 0)	{
					f_setlabel((const TCHAR *)"1:ALIENTEK_FLASH");                                    /* 设置Flash磁盘的名字为：ALIENTEK_FLASH */
					//printf("Flash Disk Format Finish\n");     /* 格式化完�? */
			}	else {
					//printf("Flash Disk Format Error \n");     /* 格式化失�? */
			}
	}
	myfree(2, work_buff);
}

//void fmout_disks(void *pvParameters){
void fmout_disks(uint8_t opt){
	fmout_sd(0);
	fmout_norflash(1);
}

// 定义�?个任务来获取 IP 地址
void vGetIPTask(void *pvParameters) {
    struct netif *netif;
    ip4_addr_t ip_addr;

    // 等待网络接口准备就绪
    while (1) {
        netif = &gnetif; // 获取网络接口指针
        if (netif != NULL && netif_is_up(netif)) {
            // 获取 IP 地址
            ip_addr = netif->ip_addr;
			//使用 ip4addr_ntoa 函数，它�? ip4_addr_t 结构体转换为字符串形式的 IP 地址，如果转换成功则表示 IP 地址是有效的
            if (ip4addr_ntoa(&ip_addr)) { //验证 IP 地址是否有效
				// 打印 IP 地址(成功获取到有线ip地址)
				//printf("IP Address: %s\n", ip4addr_ntoa(&ip_addr));
				strcpy(ETH_ip_address, ip4addr_ntoa(&ip_addr));
				printf("ETH ip address:%s\n", (char*)ETH_ip_address);
				break;
            }
        }

        // 延迟�?段时间后再次�?�?
        vTaskDelay(pdMS_TO_TICKS(1000));
    }

    // 任务完成，删除自�?
    vTaskDelete(NULL);
}
/* USER CODE END FunctionPrototypes */

void WebServer_Task(void const * argument);
void Touch_Task(void const * argument);
void IOT_Task(void const * argument);
void GUI_Task(void const * argument);

extern void MX_LWIP_Init(void);
extern void MX_FATFS_Init(void);
void MX_FREERTOS_Init(void); /* (MISRA C 2004 rule 8.1) */

void MX_FREERTOS_Init(void) {

  /* Create the thread(s) */
  /* definition and creation of WebServer */
  osThreadDef(WebServer, WebServer_Task, osPriorityHigh, 0, 256);
  WebServerHandle = osThreadCreate(osThread(WebServer), NULL);

  /* definition and creation of Touch */
  osThreadDef(Touch, Touch_Task, osPriorityAboveNormal, 0, 128);
  TouchHandle = osThreadCreate(osThread(Touch), NULL);

  /* definition and creation of IOT */
  osThreadDef(IOT, IOT_Task, osPriorityNormal, 0, 128);
  IOTHandle = osThreadCreate(osThread(IOT), NULL);

  /* definition and creation of GUI */
  osThreadDef(GUI, GUI_Task, osPriorityBelowNormal, 0, 512);
  GUIHandle = osThreadCreate(osThread(GUI), NULL);

}

void WebServer_Task(void const * argument)
{

  /* init code for LWIP */
  MX_LWIP_Init();

  /* init code for FATFS */
  MX_FATFS_Init();

  /* USER CODE BEGIN WebServer_Task */
	taskENTER_CRITICAL();           /* 进入临界�? */

	printf("WebServer_Task-------------------->\n");

	printf("MX_LWIP_Init!\n");
	printf("MX_FATFS_Init!\n");

	// 创建二�?�信号量
	xBinarySemaphoreFont = xSemaphoreCreateBinary();

	//初始化norflash和SD�?
	init_disks();
	printf("Init NORFlash and SD cards!\n");

	//挂载norflash和SD�?
	fmout_disks(1);

	printf("Mout NORFlash and SD cards!\n");

	delay_init(168);                    // 初始化自定义延时函数
	lcd_init();                             // 初始化LCD
	printf("Init lcd screen!\n");
	sprintf((char *)lcd_id, "LCD ID:%04X", lcddev.id);

	while (dht11_init())    /* DHT11初始�?* */
	{
			printf("DHT11 Error!\n");
			delay_ms(200);
	}
	printf("DHT11 init successed!\n");
	lsens_init();                           /* 初始化光敏传感器 */
	printf("Lighter lsens init down!\n");

	// 释放信号量，通知任务2可以执行�?
	xSemaphoreGive(xBinarySemaphoreFont);

	//创建互斥信号�?
	xMutexEsp8266 = xSemaphoreCreateMutex();

	//使能esp8266并开启中断接�?
	ESP8266_Enable();  //CH使能
	ESP8266_Reset();  //复位引脚拉高
	printf("Enable ESP8266 and Reset!\n");

	//启用串口1和串�?3中断接收
	/*
	printf("usart1 ok\n");
	HAL_UART_Receive_IT(&huart1, uart1_rx_buffer, RX_BUFFER_SIZE);
	*/
	//HAL_UART_Receive_IT(&huart3, uart3_rx_buffer, RX_BUFFER_SIZE);
	//HAL_UART_Receive_IT(&huart3, uart3_rx_buffer, MAX_RX_BUFFER_SIZE);  //开启串口3 普通中断方式
	//HAL_UART_Receive_DMA(&huart3, uart3_rx_buffer, BUFFER_WINDOW);  //开启串口3 DMA方式

	//启用串口3DMA接收
	//USART3_Init_DMA();

	//获取有线网络ip地址
	//创建�?个FreeRTOS任务来获�? IP 地址
    xTaskCreate(vGetIPTask, "GetIP", configMINIMAL_STACK_SIZE, NULL, tskIDLE_PRIORITY + 1, NULL);

	/*
	// 等待网络接口准备就绪
	ip4_addr_t ip_addr;
    while (1) {
        if (netif_is_up(&gnetif)) {  //�?查网络接口是否已经启动并准备获取ip
            // 获取 IP 地址
            ip_addr = gnetif.ip_addr;
			// 打印 IP 地址
			printf("IP Address: %s\n", ip4addr_ntoa(&ip_addr));
			break;
        }

        // 延迟�?段时间后再次�?�?
        vTaskDelay(pdMS_TO_TICKS(1000));
    }
	*/

	/* Initialize HTTP server */
	//httpd_init();

	WebServer();  //创建�?�? TCP 套接�?

	memused = my_mem_perused(SRAMEX);
	sprintf((char *)paddr, "%d.%01d%%", memused / 10, memused % 10);
	printf("SRAMEX   USED: %s\n", (char *)paddr);

	printf("----------------------------------|\n\n");

	init_uart3_rx_queue();
	taskEXIT_CRITICAL();            /* 出临界段 */
	//vTaskDelete(xMountDisksTaskHandle);
    //xMountDisksTaskHandle = NULL;
  /* Infinite loop */
  for(;;)
  {
	/* Poll the HTTP server to handle incoming requests */
    //httpd_poll();
	Listen_Thread();
    osDelay(1);

    //测试打开文件
    /*
	if (xSemaphoreTake(xBinarySemaphoreFont, portMAX_DELAY) == pdTRUE) {
		taskENTER_CRITICAL();           // 进入临界�?
		FIL *fftemp;
		fftemp = (FIL *)mymalloc(SRAMEX, sizeof(FIL));  // 给文件描述符�?辟空�?
		if(NULL == fftemp){
			printf("fftemp is NULL\n");
		}
		uint8_t res = 0;
		res = f_open(fftemp, "1:SmartOfficeWeb/index.html", FA_READ);
		printf("NORFlash f_open return :%d\n", res);
		f_close(fftemp);
		myfree(SRAMEX, fftemp);
		// 释放信号�?
		xSemaphoreGive(xBinarySemaphoreFont);
		taskEXIT_CRITICAL();            // 出临界区
	}
	osDelay(1000);
	*/
  }
  /* USER CODE END WebServer_Task */
}

void Touch_Task(void const * argument)
{
  /* USER CODE BEGIN Touch_Task */
	printf("Touch_Task------------------------>\n");
	// 等待任务1完成
	if (xSemaphoreTake(xBinarySemaphoreFont, portMAX_DELAY) == pdTRUE) {
		taskENTER_CRITICAL();           /* 进入临界�? */

		if(fonts_init()){  //初始化字�?
			printf("Init font failed!\n");
		}else{
			printf("Init font successed!\n");
		}

		if(icons_init()){  //初始化图�?
			printf("Init icons failed!\n");
		}else{
			printf("Init icons successed!\n");
		}

		if(webs_init()){  //初始化图�?
			printf("Init web files failed!\n");
		}else{
			printf("Init web files successed!\n");
		}
		//show_webs_info(webstinfo);

		uint8_t res = 0;

		//测试NORFlash打开文件

		FIL *fftemp;
		fftemp = (FIL *)mymalloc(SRAMCCM, sizeof(FIL));  // 给文件描述符�?辟空�?

		//res = f_open(fftemp, "1:AlarmOn.bin", FA_READ);
		//printf("NORFlash f_open return :%d\n", res);
		//f_close(fftemp);

		//res = f_open(fftemp, "1:/img.jpg", FA_READ);
		//printf("NORFlash f_open return :%d\n", res);
		//f_close(fftemp);

		//测试SD打开文件
		/*
		res = f_open(fftemp, "0:/SYSTEM/SmartOfficeWeb/index.html", FA_READ);
		printf("SD f_open return :%d\n", res);
		f_close(fftemp);
		*/

		//res = f_open(fftemp, "0:/img.jpg", FA_READ);
		//printf("SD f_open return :%d\n", res);

		res = f_open(fftemp, "1:SmartOfficeWeb/index.html", FA_READ);
		printf("NORFlash f_open return :%d\n", res);
		f_close(fftemp);

		myfree(SRAMCCM, fftemp);

		//在WebServer_Task中完成磁盘初始化及挂载之后，只有Touch_Task中可以打�?文件
		//也就是在GUI启动之后f_open都会失败(很扯�?)
		//因此也像字库和图库那样维护网页文�?

		// 创建二�?�信号量
		xBinarySemaphoreICON = xSemaphoreCreateBinary();
		//将图库加载到外扩SRAM�?
		read_icons();
		//初始化位图结构体信息
		InitDynamicImage();

		lcd_set_backlight_by_pwm(0xFF); // 设置占空比为255，开启背光最�?
		lcd_clear(WHITE);  //清屏

		//screen touch init
		res = tp_dev.init();                      // 触摸屏初始化
		if(!res){
			printf("LCD Touch init Successful!\n");
		}

		// 释放信号量，通知任务GUI_Task可以执行�?
		//xSemaphoreGive(xBinarySemaphoreICON);
		//emwin_test_touch();  //emWin坐标获取

		// 释放信号�?
		xSemaphoreGive(xBinarySemaphoreFont);

		/*
		printf("webstinfo:%p\n", webstinfo);
		printf("webstinfo->index_html_size:%u\n", webstinfo->index_html_size);
		*/

		memused = my_mem_perused(SRAMEX);
		sprintf((char *)paddr, "%d.%01d%%", memused / 10, memused % 10);
		printf("SRAMEX   USED: %s\n", (char *)paddr);

		printf("----------------------------------|\n\n");
		taskEXIT_CRITICAL();            /* 出临界区 */
	}
  /* Infinite loop */
  for(;;)
  {
	  /*
		if (xSemaphoreTake(xBinarySemaphoreFont, portMAX_DELAY) == pdTRUE) {
			taskENTER_CRITICAL();           // 进入临界�?
			FIL *fftemp;
			fftemp = (FIL *)mymalloc(SRAMEX, sizeof(FIL));  // 给文件描述符�?辟空�?
			if(NULL == fftemp){
				printf("fftemp is NULL\n");
			}
			uint8_t res = 0;
			res = f_open(fftemp, "1:SmartOfficeWeb/index.html", FA_READ);
			printf("NORFlash f_open return :%d\n", res);
			f_close(fftemp);
			myfree(SRAMEX, fftemp);
			// 释放信号�?
			xSemaphoreGive(xBinarySemaphoreFont);
			taskEXIT_CRITICAL();            // 出临界区
	    }
	  */
		if (t % 5 == 0) /* �?200ms读取�?�? */ {
			dht11_read_data(&temperature, &humidity); /* 读取温湿度�?? */

			//printf("temperature: %d.%d\n", temperature>>8, (temperature & 0xFF));/* 显示温度 */
			//printf("humidity: %d.%d", humidity>>8, (humidity & 0xFF)); /* 显示湿度 */
		}
		if(t % 10 == 0) /* �?400ms读取�?�? */{
				adcx = lsens_get_scale_val();                                 /* 获取亮度 */
				//printf("bright:%d\n", adcx);
		}
		t++;
		//osDelay(10);
		//触摸屏需要轮询检测，否则emWin没有办法触发事件
		GUI_TOUCH_Exec();
		osDelay(40);
  }
  /* USER CODE END Touch_Task */
}

void IOT_Task(void const * argument)
{
  /* USER CODE BEGIN IOT_Task */
  printf("IOT_Task-------------------------->\n");
  //使用互斥信号量保护esp8266的初始化及配置过�?
  if (xSemaphoreTake(xMutexEsp8266, portMAX_DELAY) == pdTRUE) {
	/*
	printf("webstinfo:%p\n", webstinfo);
	printf("webstinfo->index_html_size:%u\n", webstinfo->index_html_size);
	*/

	xBinaryWireless = xSemaphoreCreateBinary();

	//taskENTER_CRITICAL();           // 进入临界�?
	ESP8266_Connect_Wifi(macUser_ESP8266_ApSsid, macUser_ESP8266_ApPwd);  //"DUOBAO", "yunshu666"
	//ESP8266_Connect_Wifi("Yunshu_Drwells", "yzy@0203yzy@0203");    //对ESP8266进行配置并连接到指定wifi
	//发起udp广播，所有在线的物联网子设备会主动连接过来从而获取它们的ip地址(废弃)
	ESP8266_startBroadCastCmd();
	//test();
	//扫描�?有wifi列表...

	AT_Flag = 0;

	xSemaphoreGive(xMutexEsp8266);

	/*
	printf("webstinfo:%p\n", webstinfo);
	printf("webstinfo->index_html_size:%u\n", webstinfo->index_html_size);
	*/

	memused = my_mem_perused(SRAMEX);
	sprintf((char *)paddr, "%d.%01d%%", memused / 10, memused % 10);
	printf("SRAMEX   USED: %s\n", (char *)paddr);
	printf("----------------------------------|\n\n");

	//taskEXIT_CRITICAL();            // 出临界区
  }
  taskENTER_CRITICAL();           // 进入临界殿
  // 释放信号量
  xSemaphoreGive(xBinaryWireless);

  // 释放信号量，通知任务GUI_Task可以执行了
  xSemaphoreGive(xBinarySemaphoreICON);
  taskEXIT_CRITICAL();            // 出临界区

  /*
  if (xSemaphoreTake(xBinarySemaphoreFont, portMAX_DELAY) == pdTRUE) {
		taskENTER_CRITICAL();           // 进入临界�?
		FIL *fftemp;
		fftemp = (FIL *)mymalloc(SRAMEX, sizeof(FIL));  // 给文件描述符�?辟空�?
		if(NULL == fftemp){
			printf("fftemp is NULL\n");
		}
		uint8_t res = 0;
		res = f_open(fftemp, "1:SmartOfficeWeb/index.html", FA_READ);
		printf("NORFlash f_open return :%d\n", res);
		f_close(fftemp);
		myfree(SRAMEX, fftemp);
		// 释放信号�?
		xSemaphoreGive(xBinarySemaphoreFont);
		taskEXIT_CRITICAL();            // 出临界区
  }
  */
  /*
  if (xSemaphoreTake(xBinaryWireless, portMAX_DELAY) == pdTRUE) {
	  //创建任务处理消息队列
	  xTaskCreate(vTaskProcessUART3RX, "vTaskProcessUART3RX", configMINIMAL_STACK_SIZE, NULL, tskIDLE_PRIORITY + 1, NULL);
  }
  */
  /* Infinite loop */
  for(;;)
  {
	osDelay(10);
	//taskENTER_CRITICAL();           /* 进入临界�? */
	//ESP8266_CheckRecvData(); // 处理网络请求 (可以成功收到)
	//taskEXIT_CRITICAL();            /* 出临界区 */
	//Listen_Thread_Wireless();
	//printf("IOT_Task for\n");

	// 从消息队列中获取数据
	if (xQueueReceive(xQueue_UART3_RX, uart3_rx_buffer, portMAX_DELAY) == pdPASS) {
		// 处理接收到的数据
		// 例如：打印数据到终端
		printf("Received: %s\n", uart3_rx_buffer);
	}

  }
  /* USER CODE END IOT_Task */
}

void GUI_Task(void const * argument)
{
  /* USER CODE BEGIN GUI_Task */
	/*
	taskENTER_CRITICAL();           // 进入临界�?

	// 等待任务1完成
	if (xSemaphoreTake(xBinarySemaphoreCheckFontsAndIconBin, portMAX_DELAY) == pdTRUE) {
		// 执行任务2的操�? // ...
		MainTask();
	}
	taskEXIT_CRITICAL();            // �?出临界段
	*/
	printf("GUI_Task-------------------------->\n");
	if (xSemaphoreTake(xBinarySemaphoreICON, portMAX_DELAY) == pdTRUE) {
		/*
		//在WebServer_Task中完成磁盘初始化及挂载之后，只有Touch_Task中可以打�?文件
		if (xSemaphoreTake(xBinarySemaphoreFont, portMAX_DELAY) == pdTRUE) {
			taskENTER_CRITICAL();           // 进入临界�?
			FIL *fftemp;
			fftemp = (FIL *)mymalloc(SRAMEX, sizeof(FIL));  // 给文件描述符�?辟空�?
			if(NULL == fftemp){
				printf("fftemp is NULL\n");
			}
			uint8_t res = 0;
			res = f_open(fftemp, "1:SmartOfficeWeb/index.html", FA_READ);
			printf("NORFlash f_open return :%d\n", res);
			f_close(fftemp);
			myfree(SRAMEX, fftemp);
			// 释放信号�?
			xSemaphoreGive(xBinarySemaphoreFont);
			taskEXIT_CRITICAL();            // 出临界区
		}
		*/
		/*
		printf("webstinfo:%p\n", webstinfo);
		printf("webstinfo->index_html_size:%u\n", webstinfo->index_html_size);
		*/

		MainTask();
	}
  /* Infinite loop */
	/*
  for(;;)
  {
    osDelay(1);
  }
	*/
  /* USER CODE END GUI_Task */
}

/************************ (C) COPYRIGHT STMicroelectronics *****END OF FILE****/
